# earlgrey register map
Vendor: lowRISC; File version: 0.1
CPU: ibex rev01, little endian, no MPU, no FPU, VTOR, 2 interrupt priority bits, 2 interrupts
Registers are 32-bit, read-write, no defined reset value unless marked. A register's access mark holds for its fields unless they carry their own. Offsets are from the block's base; [hi:lo] are bit positions; {n}, {i} and the like mark numbered series.

## OTP_CTRL — Interfaces integrated one-time programmable memory, supports scrambling, integrity and secure wipe
Base 0x40130000
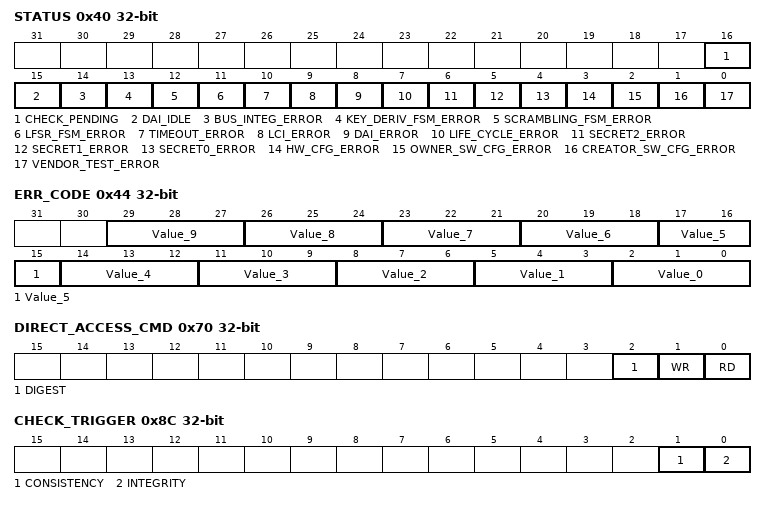
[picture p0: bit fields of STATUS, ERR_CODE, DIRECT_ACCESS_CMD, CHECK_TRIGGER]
0x40 STATUS ro — OTP status register.
  [16] CHECK_PENDING — Set to 1 if an integrity or consistency check triggered by the LFSR timer or via !!CHECK_TRIGGER is pending.
  [15] DAI_IDLE — Set to 1 if the DAI is idle and ready to accept commands.
  [14] BUS_INTEG_ERROR — This bit is set to 1 if a fatal bus integrity fault is detected.This error triggers a fatal_bus_integ_error alert.
  [13] KEY_DERIV_FSM_ERROR — Set to 1 if the key derivation FSM has reached an invalid state.This raises an fatal_check_error alert and is an unrecoverable error condition.
  [12] SCRAMBLING_FSM_ERROR — Set to 1 if the scrambling datapath FSM has reached an invalid state.This raises an fatal_check_error alert and is an unrecoverable error condition.
  [11] LFSR_FSM_ERROR — Set to 1 if the LFSR timer FSM has reached an invalid state.This raises an fatal_check_error alert and is an unrecoverable error condition.
  [10] TIMEOUT_ERROR — Set to 1 if an integrity or consistency check times out.This raises an fatal_check_error alert and is an unrecoverable error condition.
  [9] LCI_ERROR — Set to 1 if an error occurred in the LCI.If set to 1, SW should check the !!ERR_CODE register at the corresponding index.
  [8] DAI_ERROR — Set to 1 if an error occurred in the DAI.If set to 1, SW should check the !!ERR_CODE register at the corresponding index.
  [7] LIFE_CYCLE_ERROR — Set to 1 if an error occurred in this partition.If set to 1, SW should check the !!ERR_CODE register at the corresponding index.
  [6] SECRET2_ERROR — Set to 1 if an error occurred in this partition.If set to 1, SW should check the !!ERR_CODE register at the corresponding index.
  [5] SECRET1_ERROR — Set to 1 if an error occurred in this partition.If set to 1, SW should check the !!ERR_CODE register at the corresponding index.
  [4] SECRET0_ERROR — Set to 1 if an error occurred in this partition.If set to 1, SW should check the !!ERR_CODE register at the corresponding index.
  [3] HW_CFG_ERROR — Set to 1 if an error occurred in this partition.If set to 1, SW should check the !!ERR_CODE register at the corresponding index.
  [2] OWNER_SW_CFG_ERROR — Set to 1 if an error occurred in this partition.If set to 1, SW should check the !!ERR_CODE register at the corresponding index.
  [1] CREATOR_SW_CFG_ERROR — Set to 1 if an error occurred in this partition.If set to 1, SW should check the !!ERR_CODE register at the corresponding index.
  [0] VENDOR_TEST_ERROR — Set to 1 if an error occurred in this partition.If set to 1, SW should check the !!ERR_CODE register at the corresponding index.
0x44 ERR_CODE ro — This register holds information about error conditions that occurred in the agentsinteracting with the OTP macro via the internal bus. The error codes should be checkedif the partitions, DAI or LCI flag an error in the !!STATUS register, or when an!!INTR_STATE.otp_error has been triggered. Note that all errors trigger an otp_errorinterrupt, and in addition some errors may trigger either an fatal_macro_error or anfatal_check_error alert.
  [3n+2:3n] Value_{n} (n=0..9) — Value
0x6C DIRECT_ACCESS_REGWEN ro — Register write enable for all direct access interface registers.
  [0] Value — This bit is hardware-managed and only readable by software.The DAI sets this bit temporarily to 0 during an OTP operation such thatthe corresponding address and data registers cannot be modified whilethe operation is pending.
0x70 DIRECT_ACCESS_CMD — Command register for direct accesses.
  [2] DIGEST — Initiates the digest calculation and locking sequence for the partition specified by!!DIRECT_ACCESS_ADDRESS.
  [1] WR — Initiates a programming sequence that writes the data in !!DIRECT_ACCESS_WDATA_0and !!DIRECT_ACCESS_WDATA_1 (for 64bit partitions) to the location specified by!!DIRECT_ACCESS_ADDRESS.
  [0] RD — Initiates a readout sequence that reads the location specifiedby !!DIRECT_ACCESS_ADDRESS. The command places the data read into!!DIRECT_ACCESS_RDATA_0 and !!DIRECT_ACCESS_RDATA_1 (for 64bit partitions).
0x74 DIRECT_ACCESS_ADDRESS — Address register for direct accesses.
  [10:0] Value — This is the address for the OTP word to be read or written throughthe direct access interface. Note that the address is aligned to the access sizeinternally, hence bits 1:0 are ignored for 32bit accesses, and bits 2:0 are ignoredfor 64bit accesses.For the digest calculation command, set this register to the partition base offset.
0x78 DIRECT_ACCESS_WDATA_0 — Write data for direct accesses.Hardware automatically determines the access granule (32bit or 64bit) based on whichpartition is being written to.
  [31:0] Value_0 — Value
0x7C DIRECT_ACCESS_WDATA_1 — Write data for direct accesses.Hardware automatically determines the access granule (32bit or 64bit) based on whichpartition is being written to.
  [31:0] Value_1 — Value
0x80 DIRECT_ACCESS_RDATA_0 ro — Read data for direct accesses.Hardware automatically determines the access granule (32bit or 64bit) based on whichpartition is read from.
  [31:0] Value_0 — Value
0x84 DIRECT_ACCESS_RDATA_1 ro — Read data for direct accesses.Hardware automatically determines the access granule (32bit or 64bit) based on whichpartition is read from.
  [31:0] Value_1 — Value
0x88 CHECK_TRIGGER_REGWEN — Register write enable for !!CHECK_TRIGGER.
  [0] Value — When cleared to 0, the !!CHECK_TRIGGER register cannot be written anymore.Write 0 to clear this bit.
0x8C CHECK_TRIGGER — Command register for direct accesses.
  [1] CONSISTENCY — Writing 1 to this bit triggers a consistency check. SW should monitor !!STATUS.CHECK_PENDINGand wait until the check has been completed. If there are any errors, those will be flaggedin the !!STATUS and !!ERR_CODE registers, and via interrupts and alerts.
  [0] INTEGRITY — Writing 1 to this bit triggers an integrity check. SW should monitor !!STATUS.CHECK_PENDINGand wait until the check has been completed. If there are any errors, those will be flaggedin the !!STATUS and !!ERR_CODE registers, and via the interrupts and alerts.
0x90 CHECK_REGWEN — Register write enable for !!INTEGRITY_CHECK_PERIOD and !!CONSISTENCY_CHECK_PERIOD.
  [0] Value — When cleared to 0, !!INTEGRITY_CHECK_PERIOD and !!CONSISTENCY_CHECK_PERIOD registers cannot be written anymore.Write 0 to clear this bit.
0x94 CHECK_TIMEOUT — Timeout value for the integrity and consistency checks.
  [31:0] Value — Timeout value in cycles for the for the integrity and consistency checks. If an integrity or consistencycheck does not complete within the timeout window, an error will be flagged in the !!STATUS register,an otp_error interrupt will be raised, and an fatal_check_error alert will be sent out. The timeout shouldbe set to a large value to stay on the safe side. The maximum check time can be upper bounded by thenumber of cycles it takes to readout, scramble and digest the entire OTP array. Since this amounts toroughly 25k cycles, it is recommended to set this value to at least 100'000 cycles in order to stay on thesafe side. A value of zero disables the timeout mechanism (default).
0x98 INTEGRITY_CHECK_PERIOD — This value specifies the maximum period that can be generated pseudo-randomly.Only applies to the HW_CFG and SECRET* partitions once they are locked.
  [31:0] Value — The pseudo-random period is generated using a 40bit LFSR internally, and this register definesthe bit mask to be applied to the LFSR output in order to limit its range. The value of thisregister is left shifted by 8bits and the lower bits are set to 8'hFF in order to form the 40bit mask.A recommended value is 0x3_FFFF, corresponding to a maximum period of ~2.8s at 24MHz.A value of zero disables the timer (default). Note that a one-off check can always be triggered via!!CHECK_TRIGGER.INTEGRITY.
0x9C CONSISTENCY_CHECK_PERIOD — This value specifies the maximum period that can be generated pseudo-randomly.This applies to the LIFE_CYCLE partition and the HW_CFG and SECRET* partitions once they are locked.
  [31:0] Value — The pseudo-random period is generated using a 40bit LFSR internally, and this register definesthe bit mask to be applied to the LFSR output in order to limit its range. The value of thisregister is left shifted by 8bits and the lower bits are set to 8'hFF in order to form the 40bit mask.A recommended value is 0x3FF_FFFF, corresponding to a maximum period of ~716s at 24MHz.A value of zero disables the timer (default). Note that a one-off check can always be triggered via!!CHECK_TRIGGER.CONSISTENCY.
0xA0 VENDOR_TEST_READ_LOCK — Runtime read lock for the VENDOR_TEST partition.
  [0] Value — When cleared to 0, read access to the VENDOR_TEST partition is locked.Write 0 to clear this bit.
0xA4 CREATOR_SW_CFG_READ_LOCK — Runtime read lock for the CREATOR_SW_CFG partition.
  [0] Value — When cleared to 0, read access to the CREATOR_SW_CFG partition is locked.Write 0 to clear this bit.
0xA8 OWNER_SW_CFG_READ_LOCK — Runtime read lock for the OWNER_SW_CFG partition.
  [0] Value — When cleared to 0, read access to the OWNER_SW_CFG partition is locked.Write 0 to clear this bit.
0xAC VENDOR_TEST_DIGEST_0 ro — Integrity digest for the VENDOR_TEST partition.The integrity digest is 0 by default. Software must write thisdigest value via the direct access interface in order to lock the partition.After a reset, write access to the VENDOR_TEST partition is locked andthe digest becomes visible in this CSR.
  [31:0] Value_0 — Value
0xB0 VENDOR_TEST_DIGEST_1 ro — Integrity digest for the VENDOR_TEST partition.The integrity digest is 0 by default. Software must write thisdigest value via the direct access interface in order to lock the partition.After a reset, write access to the VENDOR_TEST partition is locked andthe digest becomes visible in this CSR.
  [31:0] Value_1 — Value
0xB4 CREATOR_SW_CFG_DIGEST_0 ro — Integrity digest for the CREATOR_SW_CFG partition.The integrity digest is 0 by default. Software must write thisdigest value via the direct access interface in order to lock the partition.After a reset, write access to the CREATOR_SW_CFG partition is locked andthe digest becomes visible in this CSR.
  [31:0] Value_0 — Value
0xB8 CREATOR_SW_CFG_DIGEST_1 ro — Integrity digest for the CREATOR_SW_CFG partition.The integrity digest is 0 by default. Software must write thisdigest value via the direct access interface in order to lock the partition.After a reset, write access to the CREATOR_SW_CFG partition is locked andthe digest becomes visible in this CSR.
  [31:0] Value_1 — Value
0xBC OWNER_SW_CFG_DIGEST_0 ro — Integrity digest for the OWNER_SW_CFG partition.The integrity digest is 0 by default. Software must write thisdigest value via the direct access interface in order to lock the partition.After a reset, write access to the OWNER_SW_CFG partition is locked andthe digest becomes visible in this CSR.
  [31:0] Value_0 — Value
0xC0 OWNER_SW_CFG_DIGEST_1 ro — Integrity digest for the OWNER_SW_CFG partition.The integrity digest is 0 by default. Software must write thisdigest value via the direct access interface in order to lock the partition.After a reset, write access to the OWNER_SW_CFG partition is locked andthe digest becomes visible in this CSR.
  [31:0] Value_1 — Value
0xC4 HW_CFG_DIGEST_0 ro — Integrity digest for the HW_CFG partition.The integrity digest is 0 by default. The digest calculation can be triggered via the !!DIRECT_ACCESS_CMD.After a reset, the digest then becomes visible in this CSR, and the corresponding partition becomes write-locked.
  [31:0] Value_0 — Value
0xC8 HW_CFG_DIGEST_1 ro — Integrity digest for the HW_CFG partition.The integrity digest is 0 by default. The digest calculation can be triggered via the !!DIRECT_ACCESS_CMD.After a reset, the digest then becomes visible in this CSR, and the corresponding partition becomes write-locked.
  [31:0] Value_1 — Value
{0xCC+8i} SECRET{i}_DIGEST_0 ro (i=0..2) — Integrity digest for the SECRET{i} partition.The integrity digest is 0 by default. The digest calculation can be triggered via the !!DIRECT_ACCESS_CMD.After a reset, the digest then becomes visible in this CSR, and the corresponding partition becomes write-locked.
  [31:0] Value_0 — Value
{0xD0+8i} SECRET{i}_DIGEST_1 ro (i=0..2) — Integrity digest for the SECRET{i} partition.The integrity digest is 0 by default. The digest calculation can be triggered via the !!DIRECT_ACCESS_CMD.After a reset, the digest then becomes visible in this CSR, and the corresponding partition becomes write-locked.
  [31:0] Value_1 — Value
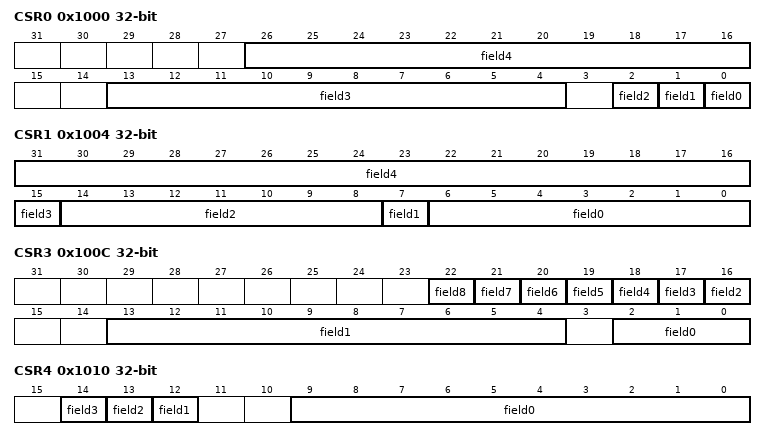
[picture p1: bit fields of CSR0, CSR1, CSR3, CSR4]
0x1000 CSR0
  [26:16] field4, [13:4] field3, [2] field2, [1] field1, [0] field0
0x1004 CSR1
  [31:16] field4, [15] field3, [14:8] field2, [7] field1, [6:0] field0
0x1008 CSR2
  [0] field0
0x100C CSR3
  [n+14] field{n} (n=2..8), [13:4] field1, [2:0] field0
0x1010 CSR4
  [14] field3, [13] field2, [12] field1, [9:0] field0
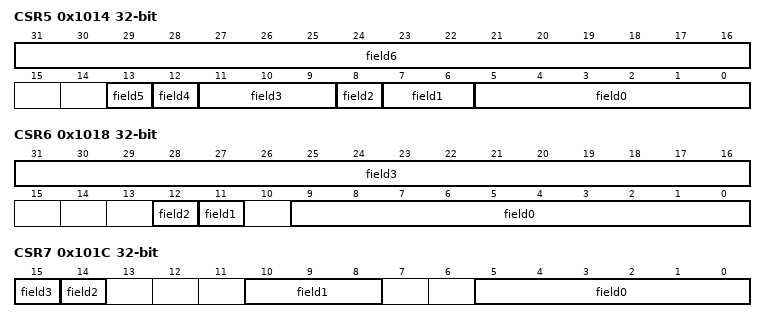
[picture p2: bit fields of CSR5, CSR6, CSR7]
0x1014 CSR5
  [31:16] field6, [13] field5, [12] field4, [11:9] field3, [8] field2, [7:6] field1, [5:0] field0
0x1018 CSR6
  [31:16] field3, [12] field2, [11] field1, [9:0] field0
0x101C CSR7 ro
  [15] field3, [14] field2, [10:8] field1, [5:0] field0
